# max32630 register map
Vendor: Maxim Integrated; Series: ARMCM4; File version: 1.1
CPU: CM4 r1p0, little endian, no MPU, FPU, 3 interrupt priority bits
Registers are 32-bit, read-write, reset 0x0 unless marked. A register's access mark holds for its fields unless they carry their own. Offsets are from the block's base; [hi:lo] are bit positions; {n}, {i} and the like mark numbered series; 'fields as' and 'values as' point back to an identical list.

## ADC — 10-bit Analog to Digital Converter
Base 0x4001F000
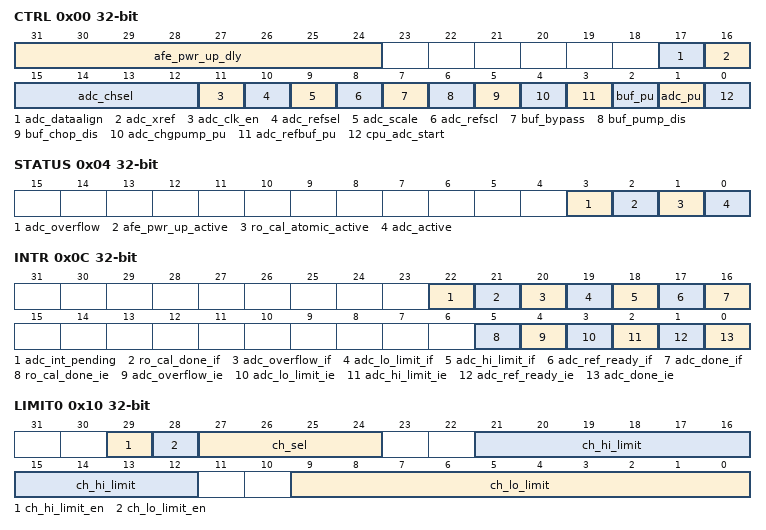
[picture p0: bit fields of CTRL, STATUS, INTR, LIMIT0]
0x00 CTRL — ADC Control
  [31:24] afe_pwr_up_dly — Delay from ADC Powerup Until ADC Ready Asserted
  [17] adc_dataalign — ADC Data Alignment Select
  [16] adc_xref — Enable Use of ADC External Reference
  [15:12] adc_chsel — ADC Channel Select
  [11] adc_clk_en — ADC Clock Enable
  [10] adc_refsel — ADC Reference (VRef) Select (INTERNAL ONLY)
  [9] adc_scale
  [8] adc_refscl — ADC Reference Scale
  [7] buf_bypass — Bypass Input Buffer
  [6] buf_pump_dis — Disable Use of Charge Pump Output by Input Buffer (INTERNAL)
  [5] buf_chop_dis — ADC Input Buffer Chop Disable (INTERNAL ONLY)
  [4] adc_chgpump_pu — ADC Charge Pump Power Up
  [3] adc_refbuf_pu — ADC Reference Buffer Power Up
  [2] buf_pu — ADC Input Buffer Power Up
  [1] adc_pu — ADC Power Up
  [0] cpu_adc_start — Start ADC Conversion
0x04 STATUS — ADC Status
  [3] adc_overflow ro
  [2] afe_pwr_up_active ro — AFE Power Up Delay Active
  [1] ro_cal_atomic_active ro — RO Frequency Calibration Active (If Atomic)
  [0] adc_active ro — ADC Conversion In Progress
0x08 DATA — ADC Output Data
  [15:0] adc_data ro — ADC Converted Sample Data Output
0x0C INTR — ADC Interrupt Control Register
  [22] adc_int_pending ro — ADC Interrupt Pending Status
  [21] ro_cal_done_if write-1-clears — RO Cal Done Interrupt Flag
  [20] adc_overflow_if write-1-clears — ADC Overflow Interrupt Flag
  [19] adc_lo_limit_if write-1-clears — ADC Lo Limit Monitor Interrupt Flag
  [18] adc_hi_limit_if write-1-clears — ADC Hi Limit Monitor Interrupt Flag
  [17] adc_ref_ready_if write-1-clears — ADC Reference Ready Interrupt Flag
  [16] adc_done_if write-1-clears — ADC Done Interrupt Flag
  [5] ro_cal_done_ie — RO Cal Done Interrupt Enable
  [4] adc_overflow_ie — ADC Overflow Interrupt Enable
  [3] adc_lo_limit_ie — ADC Lo Limit Monitor Interrupt Enable
  [2] adc_hi_limit_ie — ADC Hi Limit Monitor Interrupt Enable
  [1] adc_ref_ready_ie — ADC Reference Ready Interrupt Enable
  [0] adc_done_ie — ADC Done Interrupt Enable
0x10 LIMIT0 — ADC Limit
  [29] ch_hi_limit_en — High Limit Monitoring Enable
  [28] ch_lo_limit_en — Low Limit Monitoring Enable
  [27:24] ch_sel — ADC Channel Select
  [21:12] ch_hi_limit — High Limit Threshold
  [9:0] ch_lo_limit — Low Limit Threshold
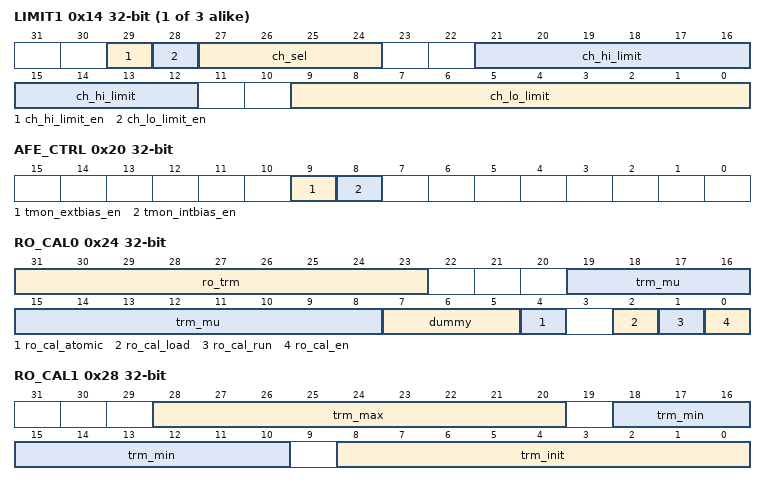
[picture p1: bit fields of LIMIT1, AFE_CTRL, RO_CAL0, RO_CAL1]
{0x10+4i} LIMIT{i} (i=1..3) — ADC Limit {i}
  fields as LIMIT0
0x20 AFE_CTRL — AFE Control Register
  [9] tmon_extbias_en — Enable external temperature measurement bias generator
  [8] tmon_intbias_en — Enable internal temperature measurement bias generator
0x24 RO_CAL0 — RO Trim Calibration Register 0
  [31:23] ro_trm — RO Trim Calibration Result
  [19:8] trm_mu — RO Trim Adaptation Gain
  [7:5] dummy — Dummy Write Field
  [4] ro_cal_atomic — RO Calibration Run Atomic
  [2] ro_cal_load — RO Calibration Load Initial Value
  [1] ro_cal_run — RO Calibration Run
  [0] ro_cal_en — RO Calibration Enable
0x28 RO_CAL1 — RO Trim Calibration Register 1
  [28:20] trm_max — RO Trim Minimum Adaptive Limit
  [18:10] trm_min — RO Trim Maximum Adaptive Limit
  [8:0] trm_init — RO Trim Initial Value
0x2C RO_CAL2 — RO Trim Calibration Register 2
  [7:0] auto_cal_done_cnt — Auto Cal Time Delay for Atomic Calibration (in milliseconds)

## SPIS — SPI Slave Interface
Base 0x40020000
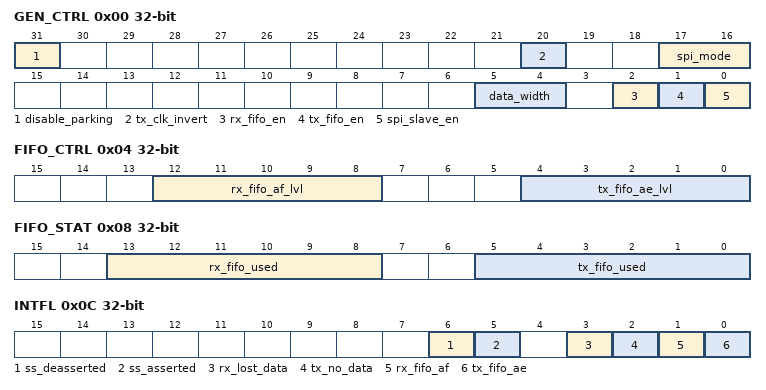
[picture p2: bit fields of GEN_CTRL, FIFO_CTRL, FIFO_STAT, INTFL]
0x00 GEN_CTRL — SPI Slave General Control Register
  [31] disable_parking — Disable automatic resetting of SPI Slave on exit from LP Modes
  [20] tx_clk_invert — Invert TX Clock
    0=no_effect; 1=Inverts the TX transmit clock such that outgoing data is updated on the opposite clock edge from that specified by spi_mode. Effectively, this inverts the value of the Clock Polarity bit from the value specified in spi_mode.
  [17:16] spi_mode — Defines Clock Polarity (bit 17) and Clock Phase (bit 16), collectively referred to as SPI Mode.
  [5:4] data_width — Width of SPI Slave Data Transfers
    0=1-bit Wide; 1=x2 (2-bit Wide/Dual); 2=x4 (4-bit Wide/Quad); 3=invalid (Reserved for future use. Do not use.)
  [2] rx_fifo_en — SPI RX FIFO Enable
    0=Disabled (Disable SPI Slave RX FIFO); 1=Enabled (Enable SPI Slave RX FIFO)
  [1] tx_fifo_en — TX FIFO Enable
    0=Disabled (Disable SPI Slave TX FIFO); 1=Enabled (Enable SPI Slave TX FIFO)
  [0] spi_slave_en — SPI Slave Enable
    0=Disabled (Disable SPI Slave); 1=Enabled (Enable SPI Slave)
0x04 FIFO_CTRL — SPI Master FIFO Control Register
  [12:8] rx_fifo_af_lvl ro — Receive FIFO Almost Full Flag Level
  [4:0] tx_fifo_ae_lvl — Transaction FIFO Almost Empty Flag Level
0x08 FIFO_STAT — SPI Slave FIFO Status Information
  [13:8] rx_fifo_used ro — Number of Bytes in Receive FIFO
  [5:0] tx_fifo_used ro — Number of Bytes in Transmit FIFO
0x0C INTFL — SPI Slave Interrupt Flags
  [6] ss_deasserted write-1-clears — Slave Select Deasserted
  [5] ss_asserted write-1-clears — Slave Select Asserted
  [3] rx_lost_data write-1-clears — RX FIFO Overflow
  [2] tx_no_data write-1-clears — TX FIFO Empty
  [1] rx_fifo_af write-1-clears — RX FIFO Almost Full
  [0] tx_fifo_ae write-1-clears — TX FIFO Almost Empty
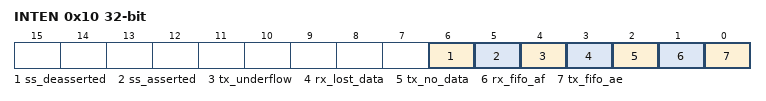
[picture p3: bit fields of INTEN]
0x10 INTEN — SPI Slave Interrupt Enable/Disable Settings
  [all] fields
    0=disabled (Disable Interrupt); 1=enabled (Enable Interrupt)
  [6] ss_deasserted — Slave Select Deasserted Int Enable
  [5] ss_asserted — Slave Select Asserted Int Enable
  [4] tx_underflow — TX Underflow Int Enable
  [3] rx_lost_data — RX FIFO Overflow Int Enable
  [2] tx_no_data — No Data in TX FIFO Int Enable
  [1] rx_fifo_af — RX FIFO Almost Full Int Enable
  [0] tx_fifo_ae — TX FIFO Almost Empty Int Enable
